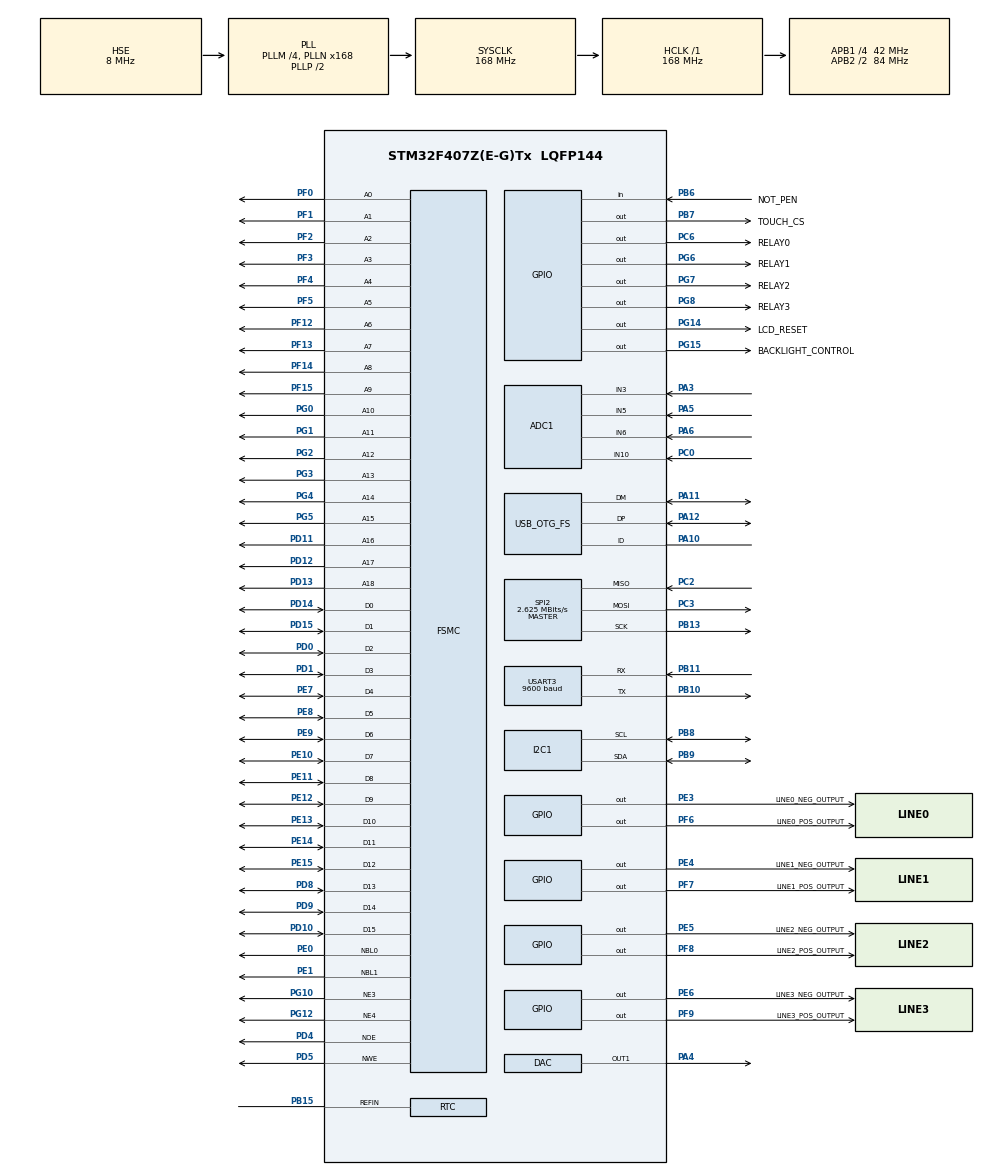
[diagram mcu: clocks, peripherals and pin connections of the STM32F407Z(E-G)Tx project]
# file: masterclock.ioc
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ADC1.Channel-0\#ChannelRegularConversion=ADC_CHANNEL_3
ADC1.Channel-1\#ChannelRegularConversion=ADC_CHANNEL_5
ADC1.Channel-2\#ChannelRegularConversion=ADC_CHANNEL_6
ADC1.Channel-3\#ChannelRegularConversion=ADC_CHANNEL_10
ADC1.ContinuousConvMode=ENABLE
ADC1.DMAContinuousRequests=ENABLE
ADC1.EOCSelection=ADC_EOC_SEQ_CONV
ADC1.EnableAnalogWatchDog=true
ADC1.HighThreshold=3500
ADC1.ITMode=ENABLE
ADC1.LowThreshold=300
ADC1.NbrOfConversion=4
ADC1.NbrOfConversionFlag=1
ADC1.Rank-0\#ChannelRegularConversion=1
ADC1.Rank-1\#ChannelRegularConversion=2
ADC1.Rank-2\#ChannelRegularConversion=3
ADC1.Rank-3\#ChannelRegularConversion=4
ADC1.SamplingTime-0\#ChannelRegularConversion=ADC_SAMPLETIME_112CYCLES
ADC1.SamplingTime-1\#ChannelRegularConversion=ADC_SAMPLETIME_112CYCLES
ADC1.SamplingTime-2\#ChannelRegularConversion=ADC_SAMPLETIME_112CYCLES
ADC1.SamplingTime-3\#ChannelRegularConversion=ADC_SAMPLETIME_3CYCLES
ADC1.ScanConvMode=ENABLE
ADC1.WatchdogMode=ADC_ANALOGWATCHDOG_ALL_REG
ADC1.master=1
Dma.ADC1.0.Direction=DMA_PERIPH_TO_MEMORY
Dma.ADC1.0.FIFOMode=DMA_FIFOMODE_DISABLE
Dma.ADC1.0.Instance=DMA2_Stream0
Dma.ADC1.0.MemDataAlignment=DMA_MDATAALIGN_HALFWORD
Dma.ADC1.0.MemInc=DMA_MINC_ENABLE
Dma.ADC1.0.Mode=DMA_NORMAL
Dma.ADC1.0.PeriphDataAlignment=DMA_PDATAALIGN_HALFWORD
Dma.ADC1.0.PeriphInc=DMA_PINC_DISABLE
Dma.ADC1.0.Priority=DMA_PRIORITY_MEDIUM
Dma.Request0=ADC1
FREERTOS.Tasks01=defaultTask,0,512,StartDefaultTask,Default,NULL,Dynamic,NULL,NULL;GUI,-3,600,vTaskGUI,Default,NULL,Dynamic,NULL,NULL;TaskLine0,0,128,vTaskLine0,Default,NULL,Dynamic,NULL,NULL;TaskLine1,0,128,vTaskLine1,Default,NULL,Dynamic,NULL,NULL;TaskLine2,0,128,vTaskLine2,Default,NULL,Dynamic,NULL,NULL;TaskLine3,-3,128,vTaskLine3,Default,NULL,Dynamic,NULL,NULL
FREERTOS.configTOTAL_HEAP_SIZE=16384
FREERTOS.configUSE_COUNTING_SEMAPHORES=1
FSMC.AddressSetupTime1=2
FSMC.AddressSetupTime2=0
FSMC.BusTurnAroundDuration1=0
FSMC.BusTurnAroundDuration2=0
FSMC.DataSetupTime1=5
FSMC.DataSetupTime2=8
FSMC.ExtendedMode1=FSMC_EXTENDED_MODE_DISABLE
FSMC.WriteOperation2=FSMC_WRITE_OPERATION_ENABLE
Mcu.Family=STM32F4
Mcu.Name=STM32F407Z(E-G)Tx
Mcu.Package=LQFP144
NVIC.ADC_IRQn=true\:15\:0\:true\:false\:true\:true\:true
NVIC.DMA2_Stream0_IRQn=true\:5\:0\:false\:false\:true\:true\:false
NVIC.PriorityGroup=NVIC_PRIORITYGROUP_4
NVIC.RTC_WKUP_IRQn=true\:15\:0\:true\:false\:true\:true\:true
NVIC.TIM1_UP_TIM10_IRQn=true\:0\:0\:false\:false\:true\:false\:false
NVIC.TIM7_IRQn=true\:15\:0\:true\:false\:true\:true\:true
NVIC.TimeBase=TIM1_UP_TIM10_IRQn
NVIC.TimeBaseIP=TIM1
PA10.Mode=OTG/Dual_Role_Device
PA10.Signal=USB_OTG_FS_ID
PA11.Mode=OTG/Dual_Role_Device
PA11.Signal=USB_OTG_FS_DM
PA12.Mode=OTG/Dual_Role_Device
PA12.Signal=USB_OTG_FS_DP
PA13.Mode=JTAG_5_pins
PA13.Signal=SYS_JTMS-SWDIO
PA14.Mode=JTAG_5_pins
PA14.Signal=SYS_JTCK-SWCLK
PA15.Mode=JTAG_5_pins
PA15.Signal=SYS_JTDI
PA3.Signal=ADCx_IN3
PA4.Signal=COMP_DAC1_group
PA5.Signal=ADCx_IN5
PA6.Signal=ADCx_IN6
PB10.Mode=Asynchronous
PB10.Signal=USART3_TX
PB11.Mode=Asynchronous
PB11.Signal=USART3_RX
PB13.Mode=Full_Duplex_Master
PB13.Signal=SPI2_SCK
PB15.Mode=Reference_Clock_Detection_Activate
PB15.Signal=RTC_REFIN
PB3.Mode=JTAG_5_pins
PB3.Signal=SYS_JTDO-SWO
PB4.Mode=JTAG_5_pins
PB4.Signal=SYS_JTRST
PB6.GPIO_Label=NOT_PEN
PB6.GPIO_PuPd=GPIO_PULLUP
PB6.Signal=GPIO_Input
PB7.GPIO_Label=TOUCH_CS
PB7.Signal=GPIO_Output
PB8.Mode=I2C
PB8.Signal=I2C1_SCL
PB9.Mode=I2C
PB9.Signal=I2C1_SDA
PC0.Signal=ADCx_IN10
PC14-OSC32_IN.Mode=LSE-External-Oscillator
PC14-OSC32_IN.Signal=RCC_OSC32_IN
PC15-OSC32_OUT.Mode=LSE-External-Oscillator
PC15-OSC32_OUT.Signal=RCC_OSC32_OUT
PC2.Mode=Full_Duplex_Master
PC2.Signal=SPI2_MISO
PC3.Mode=Full_Duplex_Master
PC3.Signal=SPI2_MOSI
PC6.GPIO_Label=RELAY0
PC6.Signal=GPIO_Output
PD0.Signal=FSMC_D2_DA2
PD1.Signal=FSMC_D3_DA3
PD10.Signal=FSMC_D15_DA15
PD11.Signal=FSMC_A16_CLE
PD12.Signal=FSMC_A17_ALE
PD13.Signal=FSMC_A18
PD14.Signal=FSMC_D0_DA0
PD15.Signal=FSMC_D1_DA1
PD4.Signal=FSMC_NOE
PD5.Signal=FSMC_NWE
PD8.Signal=FSMC_D13_DA13
PD9.Signal=FSMC_D14_DA14
PE0.Signal=FSMC_NBL0
PE1.Signal=FSMC_NBL1
PE10.Signal=FSMC_D7_DA7
PE11.Signal=FSMC_D8_DA8
PE12.Signal=FSMC_D9_DA9
PE13.Signal=FSMC_D10_DA10
PE14.Signal=FSMC_D11_DA11
PE15.Signal=FSMC_D12_DA12
PE3.GPIO_Label=LINE0_NEG_OUTPUT
PE3.Signal=GPIO_Output
PE4.GPIO_Label=LINE1_NEG_OUTPUT
PE4.Signal=GPIO_Output
PE5.GPIO_Label=LINE2_NEG_OUTPUT 
PE5.Signal=GPIO_Output
PE6.GPIO_Label=LINE3_NEG_OUTPUT
PE6.Signal=GPIO_Output
PE7.Signal=FSMC_D4_DA4
PE8.Signal=FSMC_D5_DA5
PE9.Signal=FSMC_D6_DA6
PF0.Signal=FSMC_A0
PF1.Signal=FSMC_A1
PF12.Signal=FSMC_A6
PF13.Signal=FSMC_A7
PF14.Signal=FSMC_A8
PF15.Signal=FSMC_A9
PF2.Signal=FSMC_A2
PF3.Signal=FSMC_A3
PF4.Signal=FSMC_A4
PF5.Signal=FSMC_A5
PF6.GPIO_Label=LINE0_POS_OUTPUT
PF6.Signal=GPIO_Output
PF7.GPIO_Label=LINE1_POS_OUTPUT
PF7.Signal=GPIO_Output
PF8.GPIO_Label=LINE2_POS_OUTPUT
PF8.Signal=GPIO_Output
PF9.GPIO_Label=LINE3_POS_OUTPUT
PF9.Signal=GPIO_Output
PG0.Signal=FSMC_A10
PG1.Signal=FSMC_A11
PG10.Mode=NorPsramChipSelect3_2
PG10.Signal=FSMC_NE3
PG12.Mode=NorPsramChipSelect4_1
PG12.Signal=FSMC_NE4
PG14.GPIO_Label=LCD_RESET
PG14.Signal=GPIO_Output
PG15.GPIO_Label=BACKLIGHT_CONTROL
PG15.GPIO_PuPd=GPIO_PULLDOWN
PG15.Signal=GPIO_Output
PG2.Signal=FSMC_A12
PG3.Signal=FSMC_A13
PG4.Signal=FSMC_A14
PG5.Signal=FSMC_A15
PG6.GPIO_Label=RELAY1
PG6.Signal=GPIO_Output
PG7.GPIO_Label=RELAY2
PG7.Signal=GPIO_Output
PG8.GPIO_Label=RELAY3
PG8.Signal=GPIO_Output
PH0-OSC_IN.Mode=HSE-External-Oscillator
PH0-OSC_IN.Signal=RCC_OSC_IN
PH1-OSC_OUT.Mode=HSE-External-Oscillator
PH1-OSC_OUT.Signal=RCC_OSC_OUT
ProjectManager.HeapSize=0x200
ProjectManager.StackSize=0x400
ProjectManager.TargetToolchain=Other Toolchains (GPDSC)
RCC.48MHZClocksFreq_Value=48000000
RCC.AHBFreq_Value=168000000
RCC.APB1CLKDivider=RCC_HCLK_DIV4
RCC.APB1Freq_Value=42000000
RCC.APB1TimFreq_Value=84000000
RCC.APB2CLKDivider=RCC_HCLK_DIV2
RCC.APB2Freq_Value=84000000
RCC.APB2TimFreq_Value=168000000
RCC.CortexFreq_Value=168000000
RCC.HCLKFreq_Value=168000000
RCC.HSE_VALUE=8000000
RCC.HSI_VALUE=16000000
RCC.PLLM=4
RCC.PLLN=168
RCC.PLLQ=7
RCC.SYSCLKFreq_VALUE=168000000
RCC.SYSCLKSource=RCC_SYSCLKSOURCE_PLLCLK
RCC.VCOOutputFreq_Value=336000000
RTC.Format=RTC_FORMAT_BIN
RTC.WakeUpClock=RTC_WAKEUPCLOCK_CK_SPRE_16BITS
SH.ADCx_IN10.0=ADC1_IN10,IN10
SH.ADCx_IN3.0=ADC1_IN3,IN3
SH.ADCx_IN5.0=ADC1_IN5,IN5
SH.ADCx_IN6.0=ADC1_IN6,IN6
SH.COMP_DAC1_group.0=DAC_OUT1,DAC_OUT1
SH.FSMC_A0.0=FSMC_A0,19b-a2
SH.FSMC_A1.0=FSMC_A1,19b-a2
SH.FSMC_A10.0=FSMC_A10,19b-a2
SH.FSMC_A11.0=FSMC_A11,19b-a2
SH.FSMC_A12.0=FSMC_A12,19b-a2
SH.FSMC_A13.0=FSMC_A13,19b-a2
SH.FSMC_A14.0=FSMC_A14,19b-a2
SH.FSMC_A15.0=FSMC_A15,19b-a2
SH.FSMC_A16_CLE.0=FSMC_A16,19b-a2
SH.FSMC_A17_ALE.0=FSMC_A17,19b-a2
SH.FSMC_A18.0=FSMC_A18,19b-a2
SH.FSMC_A2.0=FSMC_A2,19b-a2
SH.FSMC_A3.0=FSMC_A3,19b-a2
SH.FSMC_A4.0=FSMC_A4,19b-a2
SH.FSMC_A5.0=FSMC_A5,19b-a2
SH.FSMC_A6.0=FSMC_A6,19b-a2
SH.FSMC_A6.1=FSMC_A6,A6_1
SH.FSMC_A7.0=FSMC_A7,19b-a2
SH.FSMC_A8.0=FSMC_A8,19b-a2
SH.FSMC_A9.0=FSMC_A9,19b-a2
SH.FSMC_D0_DA0.0=FSMC_D0,16b-d1
SH.FSMC_D0_DA0.1=FSMC_D0,16b-d2
SH.FSMC_D10_DA10.0=FSMC_D10,16b-d1
SH.FSMC_D10_DA10.1=FSMC_D10,16b-d2
SH.FSMC_D11_DA11.0=FSMC_D11,16b-d1
SH.FSMC_D11_DA11.1=FSMC_D11,16b-d2
SH.FSMC_D12_DA12.0=FSMC_D12,16b-d1
SH.FSMC_D12_DA12.1=FSMC_D12,16b-d2
SH.FSMC_D13_DA13.0=FSMC_D13,16b-d1
SH.FSMC_D13_DA13.1=FSMC_D13,16b-d2
SH.FSMC_D14_DA14.0=FSMC_D14,16b-d1
SH.FSMC_D14_DA14.1=FSMC_D14,16b-d2
SH.FSMC_D15_DA15.0=FSMC_D15,16b-d1
SH.FSMC_D15_DA15.1=FSMC_D15,16b-d2
SH.FSMC_D1_DA1.0=FSMC_D1,16b-d1
SH.FSMC_D1_DA1.1=FSMC_D1,16b-d2
SH.FSMC_D2_DA2.0=FSMC_D2,16b-d1
SH.FSMC_D2_DA2.1=FSMC_D2,16b-d2
SH.FSMC_D3_DA3.0=FSMC_D3,16b-d1
SH.FSMC_D3_DA3.1=FSMC_D3,16b-d2
SH.FSMC_D4_DA4.0=FSMC_D4,16b-d1
SH.FSMC_D4_DA4.1=FSMC_D4,16b-d2
SH.FSMC_D5_DA5.0=FSMC_D5,16b-d1
SH.FSMC_D5_DA5.1=FSMC_D5,16b-d2
SH.FSMC_D6_DA6.0=FSMC_D6,16b-d1
SH.FSMC_D6_DA6.1=FSMC_D6,16b-d2
SH.FSMC_D7_DA7.0=FSMC_D7,16b-d1
SH.FSMC_D7_DA7.1=FSMC_D7,16b-d2
SH.FSMC_D8_DA8.0=FSMC_D8,16b-d1
SH.FSMC_D8_DA8.1=FSMC_D8,16b-d2
SH.FSMC_D9_DA9.0=FSMC_D9,16b-d1
SH.FSMC_D9_DA9.1=FSMC_D9,16b-d2
SH.FSMC_NBL0.0=FSMC_NBL0,2ByteEnable2
SH.FSMC_NBL1.0=FSMC_NBL1,2ByteEnable2
SH.FSMC_NOE.0=FSMC_NOE,Lcd1
SH.FSMC_NOE.1=FSMC_NOE,Sram2
SH.FSMC_NWE.0=FSMC_NWE,Lcd1
SH.FSMC_NWE.1=FSMC_NWE,Sram2
SPI2.BaudRatePrescaler=SPI_BAUDRATEPRESCALER_16
SPI2.CLKPhase=SPI_PHASE_2EDGE
SPI2.CLKPolarity=SPI_POLARITY_HIGH
SPI2.CRCCalculation=SPI_CRCCALCULATION_ENABLE
SPI2.CalculateBaudRate=2.625 MBits/s
SPI2.Direction=SPI_DIRECTION_2LINES
SPI2.Mode=SPI_MODE_MASTER
SPI2.VirtualType=VM_MASTER
TIM7.Period=62999
TIM7.Prescaler=100
USART3.BaudRate=9600
USART3.VirtualMode=VM_ASYNC
VP_CRC_VS_CRC.Mode=CRC_Activate
VP_FREERTOS_VS_ENABLE.Mode=Enabled
VP_LIBJPEG_VS_JPEGLIB.Mode=Enabled
VP_RTC_VS_RTC_Activate.Mode=RTC_Enabled
VP_RTC_VS_RTC_Calendar.Mode=RTC_Calendar
VP_RTC_VS_RTC_WakeUp_intern.Mode=WakeUp
VP_SYS_VS_tim1.Mode=TIM1
VP_TIM7_VS_ClockSourceINT.Mode=Enable_Timer
board=custom

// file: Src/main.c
/* USER CODE BEGIN Header */
/**
  ******************************************************************************
  * @file           : main.c
  * @brief          : Main program body
  ******************************************************************************
  * This notice applies to any and all portions of this file
  * that are not between comment pairs USER CODE BEGIN and
  * USER CODE END. Other portions of this file, whether
  * inserted by the user or by software development tools
  * are owned by their respective copyright owners.
  *
  * Copyright (c) 2019 STMicroelectronics International N.V.
  * All rights reserved.
  *
  * Redistribution and use in source and binary forms, with or without
  * modification, are permitted, provided that the following conditions are met:
  *
  * 1. Redistribution of source code must retain the above copyright notice,
  *    this list of conditions and the following disclaimer.
  * 2. Redistributions in binary form must reproduce the above copyright notice,
  *    this list of conditions and the following disclaimer in the documentation
  *    and/or other materials provided with the distribution.
  * 3. Neither the name of STMicroelectronics nor the names of other
  *    contributors to this software may be used to endorse or promote products
  *    derived from this software without specific written permission.
  * 4. This software, including modifications and/or derivative works of this
  *    software, must execute solely and exclusively on microcontroller or
  *    microprocessor devices manufactured by or for STMicroelectronics.
  * 5. Redistribution and use of this software other than as permitted under
  *    this license is void and will automatically terminate your rights under
  *    this license.
  *
  * THIS SOFTWARE IS PROVIDED BY STMICROELECTRONICS AND CONTRIBUTORS "AS IS"
  * AND ANY EXPRESS, IMPLIED OR STATUTORY WARRANTIES, INCLUDING, BUT NOT
  * LIMITED TO, THE IMPLIED WARRANTIES OF MERCHANTABILITY, FITNESS FOR A
  * PARTICULAR PURPOSE AND NON-INFRINGEMENT OF THIRD PARTY INTELLECTUAL PROPERTY
  * RIGHTS ARE DISCLAIMED TO THE FULLEST EXTENT PERMITTED BY LAW. IN NO EVENT
  * SHALL STMICROELECTRONICS OR CONTRIBUTORS BE LIABLE FOR ANY DIRECT, INDIRECT,
  * INCIDENTAL, SPECIAL, EXEMPLARY, OR CONSEQUENTIAL DAMAGES (INCLUDING, BUT NOT
  * LIMITED TO, PROCUREMENT OF SUBSTITUTE GOODS OR SERVICES; LOSS OF USE, DATA,
  * OR PROFITS; OR BUSINESS INTERRUPTION) HOWEVER CAUSED AND ON ANY THEORY OF
  * LIABILITY, WHETHER IN CONTRACT, STRICT LIABILITY, OR TORT (INCLUDING
  * NEGLIGENCE OR OTHERWISE) ARISING IN ANY WAY OUT OF THE USE OF THIS SOFTWARE,
  * EVEN IF ADVISED OF THE POSSIBILITY OF SUCH DAMAGE.
  *
  ******************************************************************************
  */
/* USER CODE END Header */

#include "main.h"
#include "cmsis_os.h"
#include "libjpeg.h"

/* USER CODE BEGIN Includes */
#include "GUI.h"
#include "mainMenu.h"
#include "guivars.h"
#include "lines.h"
#include "timedate.h"
#include "backup.h"
#include "crc.h"
#include  "adc.h"
#include "touch.h"
#include "sram.h"
/* USER CODE END Includes */

/* USER CODE BEGIN PD */
Variables variables;
uint8_t cnt;
RTC_TimeTypeDef sTime;
RTC_TimeTypeDef sTimePrev;
RTC_DateTypeDef sDate;
RTC_DateTypeDef sDatePrev;
WM_MESSAGE msg;
WM_MESSAGE msgButton;

uint8_t tickSecond = 0;
extern uint16_t backgroundBuffer[18];

GUI_ALLOC_INFO pInfo;
uint8_t doTimeCorrection = 0;
/* USER CODE END PD */

ADC_HandleTypeDef hadc1;
DMA_HandleTypeDef hdma_adc1;

CRC_HandleTypeDef hcrc;

DAC_HandleTypeDef hdac;

I2C_HandleTypeDef hi2c1;

RTC_HandleTypeDef hrtc;

SPI_HandleTypeDef hspi2;

TIM_HandleTypeDef htim7;

UART_HandleTypeDef huart3;

SRAM_HandleTypeDef hsram1;
SRAM_HandleTypeDef hsram2;

osThreadId defaultTaskHandle;
osThreadId GUIHandle;
osThreadId TaskLine0Handle;
osThreadId TaskLine1Handle;
osThreadId TaskLine2Handle;
osThreadId TaskLine3Handle;

void SystemClock_Config(void);
static void MX_GPIO_Init(void);
static void MX_DMA_Init(void);
static void MX_FSMC_Init(void);
static void MX_DAC_Init(void);
static void MX_CRC_Init(void);
static void MX_ADC1_Init(void);
static void MX_RTC_Init(void);
static void MX_I2C1_Init(void);
static void MX_USB_OTG_FS_USB_Init(void);
static void MX_TIM7_Init(void);
static void MX_SPI2_Init(void);
static void MX_USART3_UART_Init(void);
void StartDefaultTask(void const * argument);
void vTaskGUI(void const * argument);
void vTaskLine0(void const * argument);
void vTaskLine1(void const * argument);
void vTaskLine2(void const * argument);
void vTaskLine3(void const * argument);

/* USER CODE BEGIN 0 */
void HAL_RTCEx_WakeUpTimerEventCallback(RTC_HandleTypeDef * hrtc)
{
	tickSecond = 1;
}
/* USER CODE END 0 */

int main(void)
{

	/* MCU Configuration--------------------------------------------------------*/

	/* Reset of all peripherals, Initializes the Flash interface and the Systick. */
	HAL_Init();

	/* Configure the system clock */
	SystemClock_Config();

	/* Initialize all configured peripherals */
	MX_GPIO_Init();
	MX_DMA_Init();
	MX_FSMC_Init();
	MX_DAC_Init();
	MX_CRC_Init();
	MX_ADC1_Init();
	MX_RTC_Init();
	MX_I2C1_Init();
	MX_USB_OTG_FS_USB_Init();
	MX_TIM7_Init();
	MX_SPI2_Init();
	MX_USART3_UART_Init();
	/* USER CODE BEGIN 2 */
	__TURN_BACKLIGHT_ON;
	variables.calibrated = 1;
	initStructures();
	LinesInit();
	readLinesPolarityFromBKP();
	readSettingsFromBKP();
	/* USER CODE END 2 */

	/* Create the thread(s) */
	/* definition and creation of defaultTask */
	osThreadDef(defaultTask, StartDefaultTask, osPriorityNormal, 0, 512);
	defaultTaskHandle = osThreadCreate(osThread(defaultTask), NULL);

	/* definition and creation of GUI */
	osThreadDef(GUI, vTaskGUI, osPriorityIdle, 0, 600);
	GUIHandle = osThreadCreate(osThread(GUI), NULL);

	/* definition and creation of TaskLine0 */
	osThreadDef(TaskLine0, vTaskLine0, osPriorityNormal, 0, 128);
	TaskLine0Handle = osThreadCreate(osThread(TaskLine0), NULL);

	/* definition and creation of TaskLine1 */
	osThreadDef(TaskLine1, vTaskLine1, osPriorityNormal, 0, 128);
	TaskLine1Handle = osThreadCreate(osThread(TaskLine1), NULL);

	/* definition and creation of TaskLine2 */
	osThreadDef(TaskLine2, vTaskLine2, osPriorityNormal, 0, 128);
	TaskLine2Handle = osThreadCreate(osThread(TaskLine2), NULL);

	/* definition and creation of TaskLine3 */
	osThreadDef(TaskLine3, vTaskLine3, osPriorityIdle, 0, 128);
	TaskLine3Handle = osThreadCreate(osThread(TaskLine3), NULL);

	/* Start scheduler */
	osKernelStart();

	/* We should never get here as control is now taken by the scheduler */

	/* Infinite loop */
	while (1)
	{

	}
}

void SystemClock_Config(void)
{
	RCC_OscInitTypeDef RCC_OscInitStruct = { 0 };
	RCC_ClkInitTypeDef RCC_ClkInitStruct = { 0 };
	RCC_PeriphCLKInitTypeDef PeriphClkInitStruct = { 0 };

	/**Configure the main internal regulator output voltage
	*/
	__HAL_RCC_PWR_CLK_ENABLE();
	__HAL_PWR_VOLTAGESCALING_CONFIG(PWR_REGULATOR_VOLTAGE_SCALE1);
	/**Initializes the CPU, AHB and APB busses clocks
	*/
	RCC_OscInitStruct.OscillatorType = RCC_OSCILLATORTYPE_LSI | RCC_OSCILLATORTYPE_HSE;
	RCC_OscInitStruct.HSEState = RCC_HSE_ON;
	RCC_OscInitStruct.LSIState = RCC_LSI_ON;
	RCC_OscInitStruct.PLL.PLLState = RCC_PLL_ON;
	RCC_OscInitStruct.PLL.PLLSource = RCC_PLLSOURCE_HSE;
	RCC_OscInitStruct.PLL.PLLM = 4;
	RCC_OscInitStruct.PLL.PLLN = 168;
	RCC_OscInitStruct.PLL.PLLP = RCC_PLLP_DIV2;
	RCC_OscInitStruct.PLL.PLLQ = 7;
	if (HAL_RCC_OscConfig(&RCC_OscInitStruct) != HAL_OK)
	{
		Error_Handler();
	}
	/**Initializes the CPU, AHB and APB busses clocks
	*/
	RCC_ClkInitStruct.ClockType = RCC_CLOCKTYPE_HCLK | RCC_CLOCKTYPE_SYSCLK
	                            | RCC_CLOCKTYPE_PCLK1 | RCC_CLOCKTYPE_PCLK2;
	RCC_ClkInitStruct.SYSCLKSource = RCC_SYSCLKSOURCE_PLLCLK;
	RCC_ClkInitStruct.AHBCLKDivider = RCC_SYSCLK_DIV1;
	RCC_ClkInitStruct.APB1CLKDivider = RCC_HCLK_DIV4;
	RCC_ClkInitStruct.APB2CLKDivider = RCC_HCLK_DIV2;

	if (HAL_RCC_ClockConfig(&RCC_ClkInitStruct, FLASH_LATENCY_5) != HAL_OK)
	{
		Error_Handler();
	}
	PeriphClkInitStruct.PeriphClockSelection = RCC_PERIPHCLK_RTC;
	PeriphClkInitStruct.RTCClockSelection = RCC_RTCCLKSOURCE_LSI;
	if (HAL_RCCEx_PeriphCLKConfig(&PeriphClkInitStruct) != HAL_OK)
	{
		Error_Handler();
	}
}

static void MX_ADC1_Init(void)
{

	ADC_AnalogWDGConfTypeDef AnalogWDGConfig = { 0 };
	ADC_ChannelConfTypeDef sConfig = { 0 };

	/**Configure the global features of the ADC (Clock, Resolution, Data Alignment and number of conversion)
	*/
	hadc1.Instance = ADC1;
	hadc1.Init.ClockPrescaler = ADC_CLOCK_SYNC_PCLK_DIV4;
	hadc1.Init.Resolution = ADC_RESOLUTION_12B;
	hadc1.Init.ScanConvMode = ENABLE;
	hadc1.Init.ContinuousConvMode = ENABLE;
	hadc1.Init.DiscontinuousConvMode = DISABLE;
	hadc1.Init.ExternalTrigConvEdge = ADC_EXTERNALTRIGCONVEDGE_NONE;
	hadc1.Init.ExternalTrigConv = ADC_SOFTWARE_START;
	hadc1.Init.DataAlign = ADC_DATAALIGN_RIGHT;
	hadc1.Init.NbrOfConversion = 4;
	hadc1.Init.DMAContinuousRequests = ENABLE;
	hadc1.Init.EOCSelection = ADC_EOC_SEQ_CONV;
	if (HAL_ADC_Init(&hadc1) != HAL_OK)
	{
		Error_Handler();
	}
	/**Configure the analog watchdog
	*/
	AnalogWDGConfig.WatchdogMode = ADC_ANALOGWATCHDOG_ALL_REG;
	AnalogWDGConfig.HighThreshold = 3500;
	AnalogWDGConfig.LowThreshold = 300;
	AnalogWDGConfig.ITMode = ENABLE;
	if (HAL_ADC_AnalogWDGConfig(&hadc1, &AnalogWDGConfig) != HAL_OK)
	{
		Error_Handler();
	}
	/**Configure for the selected ADC regular channel its corresponding rank in the sequencer and its sample time.
	*/
	sConfig.Channel = ADC_CHANNEL_3;
	sConfig.Rank = 1;
	sConfig.SamplingTime = ADC_SAMPLETIME_112CYCLES;
	if (HAL_ADC_ConfigChannel(&hadc1, &sConfig) != HAL_OK)
	{
		Error_Handler();
	}
	/**Configure for the selected ADC regular channel its corresponding rank in the sequencer and its sample time.
	*/
	sConfig.Channel = ADC_CHANNEL_5;
	sConfig.Rank = 2;
	if (HAL_ADC_ConfigChannel(&hadc1, &sConfig) != HAL_OK)
	{
		Error_Handler();
	}
	/**Configure for the selected ADC regular channel its corresponding rank in the sequencer and its sample time.
	*/
	sConfig.Channel = ADC_CHANNEL_6;
	sConfig.Rank = 3;
	if (HAL_ADC_ConfigChannel(&hadc1, &sConfig) != HAL_OK)
	{
		Error_Handler();
	}
	/**Configure for the selected ADC regular channel its corresponding rank in the sequencer and its sample time.
	*/
	sConfig.Channel = ADC_CHANNEL_10;
	sConfig.Rank = 4;
	sConfig.SamplingTime = ADC_SAMPLETIME_3CYCLES;
	if (HAL_ADC_ConfigChannel(&hadc1, &sConfig) != HAL_OK)
	{
		Error_Handler();
	}

}

static void MX_CRC_Init(void)
{

	hcrc.Instance = CRC;
	if (HAL_CRC_Init(&hcrc) != HAL_OK)
	{
		Error_Handler();
	}

}

static void MX_DAC_Init(void)
{

	DAC_ChannelConfTypeDef sConfig = { 0 };

	/**DAC Initialization
	*/
	hdac.Instance = DAC;
	if (HAL_DAC_Init(&hdac) != HAL_OK)
	{
		Error_Handler();
	}
	/**DAC channel OUT1 config
	*/
	sConfig.DAC_Trigger = DAC_TRIGGER_NONE;
	sConfig.DAC_OutputBuffer = DAC_OUTPUTBUFFER_ENABLE;
	if (HAL_DAC_ConfigChannel(&hdac, &sConfig, DAC_CHANNEL_1) != HAL_OK)
	{
		Error_Handler();
	}

}

static void MX_I2C1_Init(void)
{

	hi2c1.Instance = I2C1;
	hi2c1.Init.ClockSpeed = 100000;
	hi2c1.Init.DutyCycle = I2C_DUTYCYCLE_2;
	hi2c1.Init.OwnAddress1 = 0;
	hi2c1.Init.AddressingMode = I2C_ADDRESSINGMODE_7BIT;
	hi2c1.Init.DualAddressMode = I2C_DUALADDRESS_DISABLE;
	hi2c1.Init.OwnAddress2 = 0;
	hi2c1.Init.GeneralCallMode = I2C_GENERALCALL_DISABLE;
	hi2c1.Init.NoStretchMode = I2C_NOSTRETCH_DISABLE;
	if (HAL_I2C_Init(&hi2c1) != HAL_OK)
	{
		Error_Handler();
	}

}

static void MX_RTC_Init(void)
{

	RTC_TimeTypeDef sTime = { 0 };
	RTC_DateTypeDef sDate = { 0 };

	/**Initialize RTC Only
	*/
	hrtc.Instance = RTC;
	hrtc.Init.HourFormat = RTC_HOURFORMAT_24;
	hrtc.Init.AsynchPrediv = 127;
	hrtc.Init.SynchPrediv = 255;
	hrtc.Init.OutPut = RTC_OUTPUT_DISABLE;
	hrtc.Init.OutPutPolarity = RTC_OUTPUT_POLARITY_HIGH;
	hrtc.Init.OutPutType = RTC_OUTPUT_TYPE_OPENDRAIN;
	if (HAL_RTC_Init(&hrtc) != HAL_OK)
	{
		Error_Handler();
	}

	/* USER CODE BEGIN Check_RTC_BKUP */
	if ((RCC->BDCR & RCC_BDCR_RTCEN) == 0)
	{
		sTime.Hours = 0;
		sTime.Minutes = 0;
		sTime.Seconds = 0;
		sTime.DayLightSaving = RTC_DAYLIGHTSAVING_NONE;
		sTime.StoreOperation = RTC_STOREOPERATION_RESET;
		if (HAL_RTC_SetTime(&hrtc, &sTime, RTC_FORMAT_BIN) != HAL_OK)
		{
			Error_Handler();
		}
		sDate.WeekDay = RTC_WEEKDAY_MONDAY;
		sDate.Month = RTC_MONTH_JANUARY;
		sDate.Date = 1;
		sDate.Year = 0;

		if (HAL_RTC_SetDate(&hrtc, &sDate, RTC_FORMAT_BIN) != HAL_OK)
		{
			Error_Handler();
		}
	}
	/* USER CODE END Check_RTC_BKUP */

	/**Initialize RTC and set the Time and Date
	*/

		/**Enable the WakeUp
		*/
	if (HAL_RTCEx_SetWakeUpTimer_IT(&hrtc, 0, RTC_WAKEUPCLOCK_CK_SPRE_16BITS) != HAL_OK)
	{
		Error_Handler();
	}
	/**Enable the reference Clock input
	*/
	if (HAL_RTCEx_SetRefClock(&hrtc) != HAL_OK)
	{
		Error_Handler();
	}

}

static void MX_SPI2_Init(void)
{

	/* SPI2 parameter configuration*/
	hspi2.Instance = SPI2;
	hspi2.Init.Mode = SPI_MODE_MASTER;
	hspi2.Init.Direction = SPI_DIRECTION_2LINES;
	hspi2.Init.DataSize = SPI_DATASIZE_8BIT;
	hspi2.Init.CLKPolarity = SPI_POLARITY_HIGH;
	hspi2.Init.CLKPhase = SPI_PHASE_2EDGE;
	hspi2.Init.NSS = SPI_NSS_SOFT;
	hspi2.Init.BaudRatePrescaler = SPI_BAUDRATEPRESCALER_16;
	hspi2.Init.FirstBit = SPI_FIRSTBIT_MSB;
	hspi2.Init.TIMode = SPI_TIMODE_DISABLE;
	hspi2.Init.CRCCalculation = SPI_CRCCALCULATION_ENABLE;
	hspi2.Init.CRCPolynomial = 10;
	if (HAL_SPI_Init(&hspi2) != HAL_OK)
	{
		Error_Handler();
	}

}

static void MX_TIM7_Init(void)
{

	TIM_MasterConfigTypeDef sMasterConfig = { 0 };

	htim7.Instance = TIM7;
	htim7.Init.Prescaler = 100;
	htim7.Init.CounterMode = TIM_COUNTERMODE_UP;
	htim7.Init.Period = 62999;
	if (HAL_TIM_Base_Init(&htim7) != HAL_OK)
	{
		Error_Handler();
	}
	sMasterConfig.MasterOutputTrigger = TIM_TRGO_RESET;
	sMasterConfig.MasterSlaveMode = TIM_MASTERSLAVEMODE_DISABLE;
	if (HAL_TIMEx_MasterConfigSynchronization(&htim7, &sMasterConfig) != HAL_OK)
	{
		Error_Handler();
	}

}

static void MX_USART3_UART_Init(void)
{

	huart3.Instance = USART3;
	huart3.Init.BaudRate = 9600;
	huart3.Init.WordLength = UART_WORDLENGTH_8B;
	huart3.Init.StopBits = UART_STOPBITS_1;
	huart3.Init.Parity = UART_PARITY_NONE;
	huart3.Init.Mode = UART_MODE_TX_RX;
	huart3.Init.HwFlowCtl = UART_HWCONTROL_NONE;
	huart3.Init.OverSampling = UART_OVERSAMPLING_16;
	if (HAL_UART_Init(&huart3) != HAL_OK)
	{
		Error_Handler();
	}

}

static void MX_USB_OTG_FS_USB_Init(void)
{

}

static void MX_DMA_Init(void)
{
	/* DMA controller clock enable */
	__HAL_RCC_DMA2_CLK_ENABLE();

	/* DMA interrupt init */
	/* DMA2_Stream0_IRQn interrupt configuration */
	HAL_NVIC_SetPriority(DMA2_Stream0_IRQn, 5, 0);
	HAL_NVIC_EnableIRQ(DMA2_Stream0_IRQn);

}

static void MX_GPIO_Init(void)
{
	GPIO_InitTypeDef GPIO_InitStruct = { 0 };

	/* GPIO Ports Clock Enable */
	__HAL_RCC_GPIOE_CLK_ENABLE();
	__HAL_RCC_GPIOC_CLK_ENABLE();
	__HAL_RCC_GPIOF_CLK_ENABLE();
	__HAL_RCC_GPIOH_CLK_ENABLE();
	__HAL_RCC_GPIOA_CLK_ENABLE();
	__HAL_RCC_GPIOG_CLK_ENABLE();
	__HAL_RCC_GPIOB_CLK_ENABLE();
	__HAL_RCC_GPIOD_CLK_ENABLE();

	/*Configure GPIO pin Output Level */
	HAL_GPIO_WritePin(GPIOE, LINE0_NEG_OUTPUT_Pin | LINE1_NEG_OUTPUT_Pin | LINE2_NEG_OUTPUT_Pin | LINE3_NEG_OUTPUT_Pin, GPIO_PIN_RESET);

	/*Configure GPIO pin Output Level */
	HAL_GPIO_WritePin(GPIOF, LINE0_POS_OUTPUT_Pin | LINE1_POS_OUTPUT_Pin | LINE2_POS_OUTPUT_Pin | LINE3_POS_OUTPUT_Pin, GPIO_PIN_RESET);

	/*Configure GPIO pin Output Level */
	HAL_GPIO_WritePin(GPIOG,
		RELAY1_Pin|RELAY2_Pin|RELAY3_Pin|LCD_RESET_Pin
	                        |BACKLIGHT_CONTROL_Pin,
		GPIO_PIN_RESET);

	/*Configure GPIO pin Output Level */
	HAL_GPIO_WritePin(RELAY0_GPIO_Port, RELAY0_Pin, GPIO_PIN_RESET);

	/*Configure GPIO pin Output Level */
	HAL_GPIO_WritePin(TOUCH_CS_GPIO_Port, TOUCH_CS_Pin, GPIO_PIN_RESET);

	/*Configure GPIO pins : LINE0_NEG_OUTPUT_Pin LINE1_NEG_OUTPUT_Pin LINE2_NEG_OUTPUT_Pin LINE3_NEG_OUTPUT_Pin */
	GPIO_InitStruct.Pin = LINE0_NEG_OUTPUT_Pin | LINE1_NEG_OUTPUT_Pin | LINE2_NEG_OUTPUT_Pin | LINE3_NEG_OUTPUT_Pin;
	GPIO_InitStruct.Mode = GPIO_MODE_OUTPUT_PP;
	GPIO_InitStruct.Pull = GPIO_NOPULL;
	GPIO_InitStruct.Speed = GPIO_SPEED_FREQ_LOW;
	HAL_GPIO_Init(GPIOE, &GPIO_InitStruct);

	/*Configure GPIO pins : LINE0_POS_OUTPUT_Pin LINE1_POS_OUTPUT_Pin LINE2_POS_OUTPUT_Pin LINE3_POS_OUTPUT_Pin */
	GPIO_InitStruct.Pin = LINE0_POS_OUTPUT_Pin | LINE1_POS_OUTPUT_Pin | LINE2_POS_OUTPUT_Pin | LINE3_POS_OUTPUT_Pin;
	GPIO_InitStruct.Mode = GPIO_MODE_OUTPUT_PP;
	GPIO_InitStruct.Pull = GPIO_NOPULL;
	GPIO_InitStruct.Speed = GPIO_SPEED_FREQ_LOW;
	HAL_GPIO_Init(GPIOF, &GPIO_InitStruct);

	/*Configure GPIO pins : RELAY1_Pin RELAY2_Pin RELAY3_Pin LCD_RESET_Pin */
	GPIO_InitStruct.Pin = RELAY1_Pin | RELAY2_Pin | RELAY3_Pin | LCD_RESET_Pin;
	GPIO_InitStruct.Mode = GPIO_MODE_OUTPUT_PP;
	GPIO_InitStruct.Pull = GPIO_NOPULL;
	GPIO_InitStruct.Speed = GPIO_SPEED_FREQ_LOW;
	HAL_GPIO_Init(GPIOG, &GPIO_InitStruct);

	/*Configure GPIO pin : RELAY0_Pin */
	GPIO_InitStruct.Pin = RELAY0_Pin;
	GPIO_InitStruct.Mode = GPIO_MODE_OUTPUT_PP;
	GPIO_InitStruct.Pull = GPIO_NOPULL;
	GPIO_InitStruct.Speed = GPIO_SPEED_FREQ_LOW;
	HAL_GPIO_Init(RELAY0_GPIO_Port, &GPIO_InitStruct);

	/*Configure GPIO pins : PA10 PA11 PA12 */
	GPIO_InitStruct.Pin = GPIO_PIN_10 | GPIO_PIN_11 | GPIO_PIN_12;
	GPIO_InitStruct.Mode = GPIO_MODE_AF_PP;
	GPIO_InitStruct.Pull = GPIO_NOPULL;
	GPIO_InitStruct.Speed = GPIO_SPEED_FREQ_VERY_HIGH;
	GPIO_InitStruct.Alternate = GPIO_AF10_OTG_FS;
	HAL_GPIO_Init(GPIOA, &GPIO_InitStruct);

	/*Configure GPIO pin : BACKLIGHT_CONTROL_Pin */
	GPIO_InitStruct.Pin = BACKLIGHT_CONTROL_Pin;
	GPIO_InitStruct.Mode = GPIO_MODE_OUTPUT_PP;
	GPIO_InitStruct.Pull = GPIO_PULLDOWN;
	GPIO_InitStruct.Speed = GPIO_SPEED_FREQ_LOW;
	HAL_GPIO_Init(BACKLIGHT_CONTROL_GPIO_Port, &GPIO_InitStruct);

	/*Configure GPIO pin : NOT_PEN_Pin */
	GPIO_InitStruct.Pin = NOT_PEN_Pin;
	GPIO_InitStruct.Mode = GPIO_MODE_INPUT;
	GPIO_InitStruct.Pull = GPIO_PULLUP;
	HAL_GPIO_Init(NOT_PEN_GPIO_Port, &GPIO_InitStruct);

	/*Configure GPIO pin : TOUCH_CS_Pin */
	GPIO_InitStruct.Pin = TOUCH_CS_Pin;
	GPIO_InitStruct.Mode = GPIO_MODE_OUTPUT_PP;
	GPIO_InitStruct.Pull = GPIO_NOPULL;
	GPIO_InitStruct.Speed = GPIO_SPEED_FREQ_LOW;
	HAL_GPIO_Init(TOUCH_CS_GPIO_Port, &GPIO_InitStruct);

}

/* FSMC initialization function */
static void MX_FSMC_Init(void)
{
	FSMC_NORSRAM_TimingTypeDef Timing;

	/** Perform the SRAM1 memory initialization sequence
	*/
	hsram1.Instance = FSMC_NORSRAM_DEVICE;
	hsram1.Extended = FSMC_NORSRAM_EXTENDED_DEVICE;
	/* hsram1.Init */
	hsram1.Init.NSBank = FSMC_NORSRAM_BANK4;
	hsram1.Init.DataAddressMux = FSMC_DATA_ADDRESS_MUX_DISABLE;
	hsram1.Init.MemoryType = FSMC_MEMORY_TYPE_SRAM;
	hsram1.Init.MemoryDataWidth = FSMC_NORSRAM_MEM_BUS_WIDTH_16;
	hsram1.Init.BurstAccessMode = FSMC_BURST_ACCESS_MODE_DISABLE;
	hsram1.Init.WaitSignalPolarity = FSMC_WAIT_SIGNAL_POLARITY_LOW;
	hsram1.Init.WrapMode = FSMC_WRAP_MODE_DISABLE;
	hsram1.Init.WaitSignalActive = FSMC_WAIT_TIMING_BEFORE_WS;
	hsram1.Init.WriteOperation = FSMC_WRITE_OPERATION_ENABLE;
	hsram1.Init.WaitSignal = FSMC_WAIT_SIGNAL_DISABLE;
	hsram1.Init.ExtendedMode = FSMC_EXTENDED_MODE_DISABLE;
	hsram1.Init.AsynchronousWait = FSMC_ASYNCHRONOUS_WAIT_DISABLE;
	hsram1.Init.WriteBurst = FSMC_WRITE_BURST_DISABLE;
	hsram1.Init.PageSize = FSMC_PAGE_SIZE_NONE;
	/* Timing */
	Timing.AddressSetupTime = 2;
	Timing.AddressHoldTime = 15;
	Timing.DataSetupTime = 5;
	Timing.BusTurnAroundDuration = 0;
	Timing.CLKDivision = 16;
	Timing.DataLatency = 17;
	Timing.AccessMode = FSMC_ACCESS_MODE_A;
	/* ExtTiming */

	if (HAL_SRAM_Init(&hsram1, &Timing, NULL) != HAL_OK)
	{
		Error_Handler();
	}

	/** Perform the SRAM2 memory initialization sequence
	*/
	hsram2.Instance = FSMC_NORSRAM_DEVICE;
	hsram2.Extended = FSMC_NORSRAM_EXTENDED_DEVICE;
	/* hsram2.Init */
	hsram2.Init.NSBank = FSMC_NORSRAM_BANK3;
	hsram2.Init.DataAddressMux = FSMC_DATA_ADDRESS_MUX_DISABLE;
	hsram2.Init.MemoryType = FSMC_MEMORY_TYPE_SRAM;
	hsram2.Init.MemoryDataWidth = FSMC_NORSRAM_MEM_BUS_WIDTH_16;
	hsram2.Init.BurstAccessMode = FSMC_BURST_ACCESS_MODE_DISABLE;
	hsram2.Init.WaitSignalPolarity = FSMC_WAIT_SIGNAL_POLARITY_LOW;
	hsram2.Init.WrapMode = FSMC_WRAP_MODE_DISABLE;
	hsram2.Init.WaitSignalActive = FSMC_WAIT_TIMING_BEFORE_WS;
	hsram2.Init.WriteOperation = FSMC_WRITE_OPERATION_ENABLE;
	hsram2.Init.WaitSignal = FSMC_WAIT_SIGNAL_DISABLE;
	hsram2.Init.ExtendedMode = FSMC_EXTENDED_MODE_DISABLE;
	hsram2.Init.AsynchronousWait = FSMC_ASYNCHRONOUS_WAIT_DISABLE;
	hsram2.Init.WriteBurst = FSMC_WRITE_BURST_DISABLE;
	hsram2.Init.PageSize = FSMC_PAGE_SIZE_NONE;
	/* Timing */
	Timing.AddressSetupTime = 0;
	Timing.AddressHoldTime = 15;
	Timing.DataSetupTime = 8;
	Timing.BusTurnAroundDuration = 0;
	Timing.CLKDivision = 16;
	Timing.DataLatency = 17;
	Timing.AccessMode = FSMC_ACCESS_MODE_A;
	/* ExtTiming */

	if (HAL_SRAM_Init(&hsram2, &Timing, NULL) != HAL_OK)
	{
		Error_Handler();
	}

}

void StartDefaultTask(void const * argument)
{
	/* init code for LIBJPEG */
	MX_LIBJPEG_Init();

	/* USER CODE BEGIN 5 */
		/* Infinite loop */
	for (;;)
	{
		osDelay(50);

		touch_control(&variables);
		refreshCurrentMeter(masterClock.currentSense);
		if (masterClock.longPressCNT->it)
		{
			longPressControl();
		}
	}
	/* USER CODE END 5 */
}

void vTaskGUI(void const * argument)
{
	/* USER CODE BEGIN vTaskGUI */
	uint16_t i = 0;

	GUI_Init();
	Calibrate(&variables);
	HAL_RTC_GetDate(&hrtc, &sDate, RTC_FORMAT_BIN);
	CreateMainMenu();
	HAL_RTC_GetTime(&hrtc, &sTime, RTC_FORMAT_BIN);
	masterClock.line[0].TimeZone = masterClock.daylightSaving->timeZone;
	pollLinesOutput(10);
	/* Infinite loop */
	for (; ;)
	{

		GUI_Delay(250);
		GUI_ALLOC_GetMemInfo(&pInfo);

		if (tickSecond) //см. callback  HAL_RTCEx_RTCEventCallback
			{
				HAL_RTC_GetTime(&hrtc, &sTime, RTC_FORMAT_BIN);
				//калибровка
				if(sTime.Hours == 0 && sTime.Minutes == 0 && sTime.Seconds == 0)
				{
					timeCalibr.isCalibrated = false;
					masterClock.daylightSaving->needToShift = true;
				}
				//коррекция происходит в 01:02:00
				if(doTimeCorrection || (sTime.Hours == 1 && sTime.Minutes == 2 && sTime.Seconds == 30))
				{

					if (masterClock.timeCalibration->seconds != 0 && masterClock.timeCalibration->days != 0 && timeCalibr.isCalibrated == false) //если калибровка включена
						{
							masterClock.timeCalibration->daysPassed++;
							if (masterClock.timeCalibration->daysPassed == masterClock.timeCalibration->days) //если настал день калибровки
								{
									if (masterClock.timeCalibration->seconds > 0) //если добавить секунды
										{
											sTime.Seconds += masterClock.timeCalibration->seconds;                                         //прибавили секунды
											if(HAL_RTC_SetTime(&hrtc, &sTime, RTC_FORMAT_BIN) != HAL_OK)
											{
												Error_Handler();
											}
										}
									if (masterClock.timeCalibration->seconds < 0) //если убавить секунды
										{
											sTime.Seconds += masterClock.timeCalibration->seconds;                                          //прибавили секунды
											if(HAL_RTC_SetTime(&hrtc, &sTime, RTC_FORMAT_BIN) != HAL_OK)
											{
												Error_Handler();
											}
										}
									masterClock.timeCalibration->daysPassed = 0;                                         // 1 => 0
									timeCalibr.isCalibrated = true;
								}
						}
					if (doTimeCorrection || (masterClock.daylightSaving->needToShift&& masterClock.daylightSaving->enableDLS&&isDaylightSavingTimeEU(sDate.Date, sDate.Month, sDate.WeekDay)))
					{
						sTime.Hours += masterClock.daylightSaving->timeShift;
						pollLinesOutput(10);
						masterClock.daylightSaving->needToShift = false;
						if (HAL_RTC_SetTime(&hrtc, &sTime, RTC_FORMAT_BIN) != HAL_OK)
						{
							Error_Handler();
						}
					}
					doTimeCorrection = false;

				}
				if (sTimePrev.Seconds == 59) //каждую минуту
					{
						for (i = 0; i < LINES_AMOUNT; ++i)
						{
							if (masterClock.line[i].Pulses >= 0)
							{
								xSemaphoreGive(masterClock.line[i].xSemaphore);
							}
							else
							{
								masterClock.line[i].Pulses++;
							}
						}
					}
				if (sTimePrev.Hours == 23 && sTime.Hours == 0) //сменился день
					{
						saveDateToBKP();
						switch (masterClock.guiVars->menuState) {
						case MENU_STATE_MAIN:
							sendMsg(masterClock.handles->hMainMenu, WM_DATE_UPDATE);
							break;
						case MENU_STATE_TIMEDATESETUP:
							sendMsg(masterClock.handles->hTimeDateSetupMenu, WM_DATE_UPDATE);
							break;
						}
					}
				switch (masterClock.guiVars->menuState) {
				case MENU_STATE_MAIN:
					sendMsg(masterClock.handles->hMainMenu, WM_SEC_UPDATE);
					menuLocker(&masterClock.handles->hMainMenu);
					break;
				case MENU_STATE_TIMESETUP:
					sendMsg(masterClock.handles->hTimeSetupMenu, WM_SEC_UPDATE);
					menuLocker(&masterClock.handles->hTimeSetupMenu);
					break;
				case MENU_STATE_LINE1SETUP:
					sendMsg(masterClock.handles->hLineSetupMenu, WM_SEC_UPDATE);
					menuLocker(&masterClock.handles->hLineSetupMenu);
					break;
				case MENU_STATE_LINE2SETUP:
					sendMsg(masterClock.handles->hLineSetupMenu, WM_SEC_UPDATE);
					menuLocker(&masterClock.handles->hLineSetupMenu);
					break;
				case MENU_STATE_LINE3SETUP:
					sendMsg(masterClock.handles->hLineSetupMenu, WM_SEC_UPDATE);
					menuLocker(&masterClock.handles->hLineSetupMenu);
					break;
				case MENU_STATE_LINE4SETUP:
					sendMsg(masterClock.handles->hLineSetupMenu, WM_SEC_UPDATE);
					menuLocker(&masterClock.handles->hLineSetupMenu);
					break;
				case MENU_STATE_LINE1SETUP_PULSE:
					sendMsg(masterClock.handles->hLineSetupPulseMenu, WM_SEC_UPDATE);
					menuLocker(&masterClock.handles->hLineSetupPulseMenu);
					break;
				case MENU_STATE_LINE2SETUP_PULSE:
					sendMsg(masterClock.handles->hLineSetupPulseMenu, WM_SEC_UPDATE);
					menuLocker(&masterClock.handles->hLineSetupPulseMenu);
					break;
				case MENU_STATE_LINE3SETUP_PULSE:
					sendMsg(masterClock.handles->hLineSetupPulseMenu, WM_SEC_UPDATE);
					menuLocker(&masterClock.handles->hLineSetupPulseMenu);
					break;
				case MENU_STATE_LINE4SETUP_PULSE:
					sendMsg(masterClock.handles->hLineSetupPulseMenu, WM_SEC_UPDATE);
					menuLocker(&masterClock.handles->hLineSetupPulseMenu);
					break;
				case MENU_STATE_PASSWORD:
					sendMsg(masterClock.handles->hPasswordMenu, WM_SEC_UPDATE);
					break;
				case MENU_STATE_SETTINGS:
					menuLocker(&masterClock.handles->hLineSetupPulseMenu);
					break;

				}
				tickSecond = 0;
				sTimePrev = sTime;
			}

	}
	/* USER CODE END vTaskGUI */
}

void vTaskLine0(void const * argument)
{
	/* USER CODE BEGIN vTaskLine0 */
		/* Infinite loop */
	for (;;)
	{
		xSemaphoreTake(masterClock.line[0].xSemaphore, portMAX_DELAY);
		lineSendSignal(0);
		saveLineToBKP(0);
	}
	/* USER CODE END vTaskLine0 */
}

void vTaskLine1(void const * argument)
{
	/* USER CODE BEGIN vTaskLine1 */
		/* Infinite loop */
	for (;;)
	{
		xSemaphoreTake(masterClock.line[1].xSemaphore, portMAX_DELAY);
		lineSendSignal(1);
		saveLineToBKP(1);
	}
	/* USER CODE END vTaskLine1 */
}

void vTaskLine2(void const * argument)
{
	/* USER CODE BEGIN vTaskLine2 */
		/* Infinite loop */
	for (;;)
	{
		xSemaphoreTake(masterClock.line[2].xSemaphore, portMAX_DELAY);
		lineSendSignal(2);
		saveLineToBKP(2);
	}
	/* USER CODE END vTaskLine2 */
}

void vTaskLine3(void const * argument)
{
	/* USER CODE BEGIN vTaskLine3 */
		/* Infinite loop */
	for (;;)
	{
		xSemaphoreTake(masterClock.line[3].xSemaphore, portMAX_DELAY);
		lineSendSignal(3);
		saveLineToBKP(3);
	}
	/* USER CODE END vTaskLine3 */
}

void HAL_TIM_PeriodElapsedCallback(TIM_HandleTypeDef *htim)
{
	if (htim->Instance == TIM1) {
		HAL_IncTick();
	}
}

void Error_Handler(void)
{
}

/************************ (C) COPYRIGHT STMicroelectronics *****END OF FILE****/
